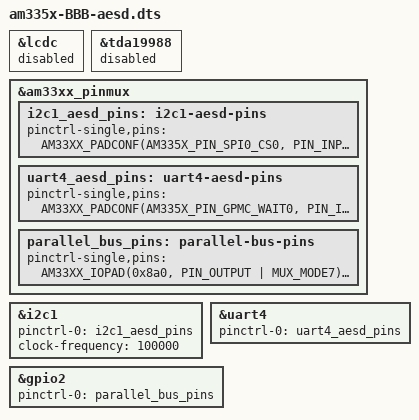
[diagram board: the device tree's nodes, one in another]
/dts-v1/;
#include "am335x-boneblack.dts"
#include <dt-bindings/pinctrl/am33xx.h>


/* Free the LCD/HDMI pins used by the parallel bus */
&lcdc     { status = "disabled"; };
&tda19988 { status = "disabled"; };

&am33xx_pinmux {
	i2c1_aesd_pins: i2c1-aesd-pins {
		pinctrl-single,pins = <
			AM33XX_PADCONF(AM335X_PIN_SPI0_CS0, PIN_INPUT_PULLUP, MUX_MODE2) /* P9.17 SCL */
			AM33XX_PADCONF(AM335X_PIN_SPI0_D1, PIN_INPUT_PULLUP, MUX_MODE2)  /* P9.18 SDA */
		>;
	};

    uart4_aesd_pins: uart4-aesd-pins {
		pinctrl-single,pins = <
			AM33XX_PADCONF(AM335X_PIN_GPMC_WAIT0, PIN_INPUT_PULLUP, MUX_MODE6)  /* P9.11 RX */
			AM33XX_PADCONF(AM335X_PIN_GPMC_WPN, PIN_OUTPUT_PULLDOWN, MUX_MODE6) /* P9.13 TX */
		>;
	};

    parallel_bus_pins: parallel-bus-pins {
		pinctrl-single,pins = <
            AM33XX_IOPAD(0x8a0, PIN_OUTPUT | MUX_MODE7)		/* D0 P8.45 gpio2_6  */
			AM33XX_IOPAD(0x8a4, PIN_OUTPUT | MUX_MODE7)		/* D1 P8.46 gpio2_7  */
			AM33XX_IOPAD(0x8a8, PIN_OUTPUT | MUX_MODE7)		/* D2 P8.43 gpio2_8  */
			AM33XX_IOPAD(0x8ac, PIN_OUTPUT | MUX_MODE7)		/* D3 P8.44 gpio2_9  */
			AM33XX_IOPAD(0x8b0, PIN_OUTPUT | MUX_MODE7)		/* D4 P8.41 gpio2_10 */
			AM33XX_IOPAD(0x8b4, PIN_OUTPUT | MUX_MODE7)		/* D5 P8.42 gpio2_11 */
			AM33XX_IOPAD(0x8b8, PIN_OUTPUT | MUX_MODE7)		/* D6 P8.39 gpio2_12 */
			AM33XX_IOPAD(0x8bc, PIN_OUTPUT | MUX_MODE7)		/* D7 P8.40 gpio2_13 */
			AM33XX_IOPAD(0x8c0, PIN_OUTPUT_PULLDOWN | MUX_MODE7)		/* lcd_rs p8.37 was lcd8*/
			AM33XX_IOPAD(0x8c4, PIN_OUTPUT_PULLDOWN | MUX_MODE7)		/* lcd_r/w   p8.38  was lcd9*/
			AM33XX_IOPAD(0x8c8, PIN_OUTPUT_PULLDOWN | MUX_MODE7)		/* lcd_e   p8.36 was lcd_data10 */
		>;
	};
};

&i2c1 {
	pinctrl-names = "default";
	pinctrl-0 = <&i2c1_aesd_pins>;
	clock-frequency = <100000>;
	status = "okay";
};

&uart4 {
	pinctrl-names = "default";
	pinctrl-0 = <&uart4_aesd_pins>;
	status = "okay";
};

&gpio2 {
	pinctrl-names = "default";
	pinctrl-0 = <&parallel_bus_pins>;
};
